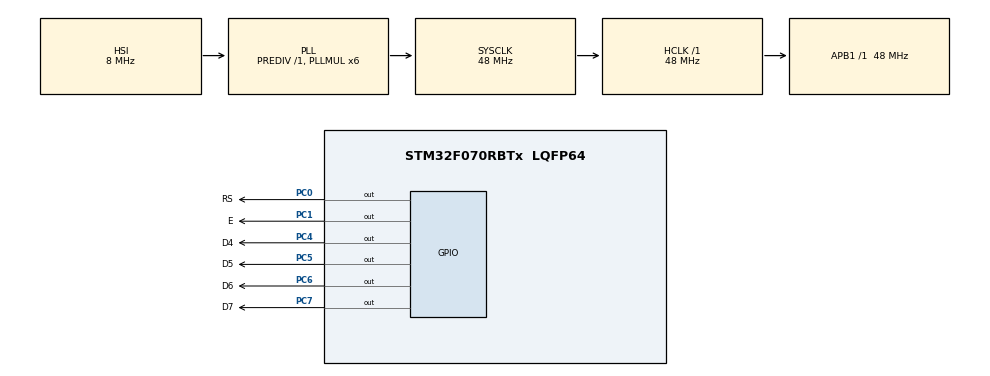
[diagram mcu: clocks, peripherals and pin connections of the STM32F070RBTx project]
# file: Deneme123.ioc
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Mcu.Family=STM32F0
Mcu.Name=STM32F070RBTx
Mcu.Package=LQFP64
PC0.GPIO_Label=RS
PC0.Signal=GPIO_Output
PC1.GPIO_Label=E
PC1.Signal=GPIO_Output
PC4.GPIO_Label=D4
PC4.Signal=GPIO_Output
PC5.GPIO_Label=D5
PC5.Signal=GPIO_Output
PC6.GPIO_Label=D6
PC6.Signal=GPIO_Output
PC7.GPIO_Label=D7
PC7.Signal=GPIO_Output
ProjectManager.HeapSize=0x200
ProjectManager.StackSize=0x400
ProjectManager.TargetToolchain=MDK-ARM V5
RCC.AHBFreq_Value=48000000
RCC.APB1Freq_Value=48000000
RCC.APB1TimFreq_Value=48000000
RCC.HCLKFreq_Value=48000000
RCC.PLLMUL=RCC_PLL_MUL6
RCC.SYSCLKFreq_VALUE=48000000
RCC.SYSCLKSource=RCC_SYSCLKSOURCE_PLLCLK
board=NUCLEO-F070RB

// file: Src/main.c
/* USER CODE BEGIN Header */
/**
  ******************************************************************************
  * @file           : main.c
  * @brief          : Main program body
  ******************************************************************************
  * @attention
  *
  * <h2><center>&copy; Copyright (c) 2019 STMicroelectronics.
  * All rights reserved.</center></h2>
  *
  * This software component is licensed by ST under BSD 3-Clause license,
  * the "License"; You may not use this file except in compliance with the
  * License. You may obtain a copy of the License at:
  *                        opensource.org/licenses/BSD-3-Clause
  *
  ******************************************************************************
  */
/* USER CODE END Header */

#include "main.h"

/* USER CODE BEGIN Includes */
#include "lcd.h"
/* USER CODE END Includes */

/* USER CODE BEGIN PD */
int8_t state;
/* USER CODE END PD */

void SystemClock_Config(void);
static void MX_GPIO_Init(void);

int main(void)
{
  HAL_Init();
  lcd_init();

  SystemClock_Config();

  MX_GPIO_Init();

  while (1)
  {
		lcd_print("Hello bro nbr!");
	  HAL_Delay(10000);
		lcd_clear();
  }

}

void SystemClock_Config(void)
{
  RCC_OscInitTypeDef RCC_OscInitStruct = {0};
  RCC_ClkInitTypeDef RCC_ClkInitStruct = {0};

  /** Initializes the CPU, AHB and APB busses clocks
  */
  RCC_OscInitStruct.OscillatorType = RCC_OSCILLATORTYPE_HSI;
  RCC_OscInitStruct.HSIState = RCC_HSI_ON;
  RCC_OscInitStruct.HSICalibrationValue = RCC_HSICALIBRATION_DEFAULT;
  RCC_OscInitStruct.PLL.PLLState = RCC_PLL_ON;
  RCC_OscInitStruct.PLL.PLLSource = RCC_PLLSOURCE_HSI;
  RCC_OscInitStruct.PLL.PLLMUL = RCC_PLL_MUL6;
  RCC_OscInitStruct.PLL.PREDIV = RCC_PREDIV_DIV1;
  if (HAL_RCC_OscConfig(&RCC_OscInitStruct) != HAL_OK)
  {
    Error_Handler();
  }
  /** Initializes the CPU, AHB and APB busses clocks
  */
  RCC_ClkInitStruct.ClockType = RCC_CLOCKTYPE_HCLK|RCC_CLOCKTYPE_SYSCLK
                              |RCC_CLOCKTYPE_PCLK1;
  RCC_ClkInitStruct.SYSCLKSource = RCC_SYSCLKSOURCE_PLLCLK;
  RCC_ClkInitStruct.AHBCLKDivider = RCC_SYSCLK_DIV1;
  RCC_ClkInitStruct.APB1CLKDivider = RCC_HCLK_DIV1;

  if (HAL_RCC_ClockConfig(&RCC_ClkInitStruct, FLASH_LATENCY_1) != HAL_OK)
  {
    Error_Handler();
  }
}

static void MX_GPIO_Init(void)
{
  GPIO_InitTypeDef GPIO_InitStruct = {0};

  /* GPIO Ports Clock Enable */
  __HAL_RCC_GPIOC_CLK_ENABLE();

  /*Configure GPIO pin Output Level */
  HAL_GPIO_WritePin(GPIOC, RS_Pin|E_Pin|D4_Pin|D5_Pin
                          |D6_Pin|D7_Pin, GPIO_PIN_RESET);

  /*Configure GPIO pins : RS_Pin E_Pin D4_Pin D5_Pin
                           D6_Pin D7_Pin */
  GPIO_InitStruct.Pin = RS_Pin|E_Pin|D4_Pin|D5_Pin
                          |D6_Pin|D7_Pin;
  GPIO_InitStruct.Mode = GPIO_MODE_OUTPUT_PP;
  GPIO_InitStruct.Pull = GPIO_NOPULL;
  GPIO_InitStruct.Speed = GPIO_SPEED_FREQ_LOW;
  HAL_GPIO_Init(GPIOC, &GPIO_InitStruct);

}

void Error_Handler(void)
{
}

/************************ (C) COPYRIGHT STMicroelectronics *****END OF FILE****/
